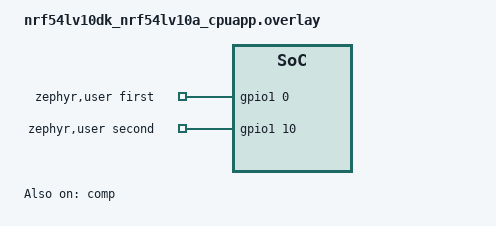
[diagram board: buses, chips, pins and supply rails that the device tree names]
/*
 * Copyright (c) 2026 Nordic Semiconductor ASA
 *
 * SPDX-License-Identifier: Apache-2.0
 */

/* Two loopbacks are used
 * Each loopback is between analog input and GPIO.
 * first-gpios (P1.00) -> AIN1 (P1.01)
 * second-gpios (P1.10, AIN5) -> (P1.11, AIN6)
 * AIN7 (P1.12) -> VDD
 */

#include <zephyr/dt-bindings/comparator/nrf-comp.h>

/ {
	aliases {
		test-comp = &comp;
	};

	zephyr,user {
		first-gpios = <&gpio1 0 GPIO_ACTIVE_HIGH>;
		second-gpios = <&gpio1 10 GPIO_ACTIVE_HIGH>;
	};
};

&gpio1 {
	status = "okay";
};

&comp {
	status = "okay";
	psel = <NRF_COMP_AIN4>;
	refsel = "AREF";
	extrefsel = <NRF_COMP_AIN3>;
	sp-mode = "NORMAL";
	th-up = <36>;
	th-down = <30>;
	isource = "DISABLED";
	enable-hyst;
};
